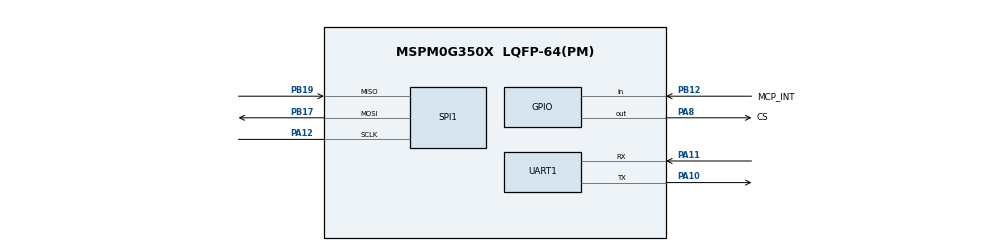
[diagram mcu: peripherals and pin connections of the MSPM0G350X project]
/**
 * @cliArgs --device "MSPM0G350X" --part "Default" --package "LQFP-64(PM)" --product "mspm0_sdk@2.10.00.04"
 * @versions {"tool":"1.26.2+4477"}
 */

/**
 * Import the modules used in this configuration.
 */
const GPIO   = scripting.addModule("/ti/driverlib/GPIO", {}, false);
const GPIO1  = GPIO.addInstance();
const SPI    = scripting.addModule("/ti/driverlib/SPI", {}, false);
const SPI1   = SPI.addInstance();
const SYSCTL = scripting.addModule("/ti/driverlib/SYSCTL");
const UART   = scripting.addModule("/ti/driverlib/UART", {}, false);
const UART1  = UART.addInstance();

/**
 * Write custom configuration values to the imported modules.
 */
GPIO1.$name                         = "SPI_PINS";
GPIO1.associatedPins.create(2);
GPIO1.associatedPins[0].$name       = "CS";
GPIO1.associatedPins[0].pin.$assign = "PA8";
GPIO1.associatedPins[1].direction   = "INPUT";
GPIO1.associatedPins[1].interruptEn = true;
GPIO1.associatedPins[1].polarity    = "FALL";
GPIO1.associatedPins[1].$name       = "MCP_INT";
GPIO1.associatedPins[1].pin.$assign = "PB12";

const Board = scripting.addModule("/ti/driverlib/Board", {}, false);

SPI1.$name                      = "SPI_0";
SPI1.peripheral.$assign         = "SPI0";
SPI1.peripheral.sclkPin.$assign = "PA12";
SPI1.peripheral.mosiPin.$assign = "PB17";
SPI1.peripheral.misoPin.$assign = "PB19";
SPI1.sclkPinConfig.$name        = "ti_driverlib_gpio_GPIOPinGeneric2";
SPI1.mosiPinConfig.$name        = "ti_driverlib_gpio_GPIOPinGeneric3";
SPI1.misoPinConfig.$name        = "ti_driverlib_gpio_GPIOPinGeneric4";
SPI1.cs0PinConfig.$name         = "ti_driverlib_gpio_GPIOPinGeneric5";

SYSCTL.forceDefaultClkConfig = true;

UART1.$name                    = "UART_0";
UART1.peripheral.rxPin.$assign = "PA11";
UART1.peripheral.txPin.$assign = "PA10";
UART1.txPinConfig.$name        = "ti_driverlib_gpio_GPIOPinGeneric0";
UART1.rxPinConfig.$name        = "ti_driverlib_gpio_GPIOPinGeneric1";

/**
 * Pinmux solution for unlocked pins/peripherals. This ensures that minor changes to the automatic solver in a future
 * version of the tool will not impact the pinmux you originally saw.  These lines can be completely deleted in order to
 * re-solve from scratch.
 */
Board.peripheral.$suggestSolution          = "DEBUGSS";
Board.peripheral.swclkPin.$suggestSolution = "PA20";
Board.peripheral.swdioPin.$suggestSolution = "PA19";
SPI1.peripheral.cs0Pin.$suggestSolution    = "PA2";
SYSCTL.peripheral.$suggestSolution         = "SYSCTL";
UART1.peripheral.$suggestSolution          = "UART0";
